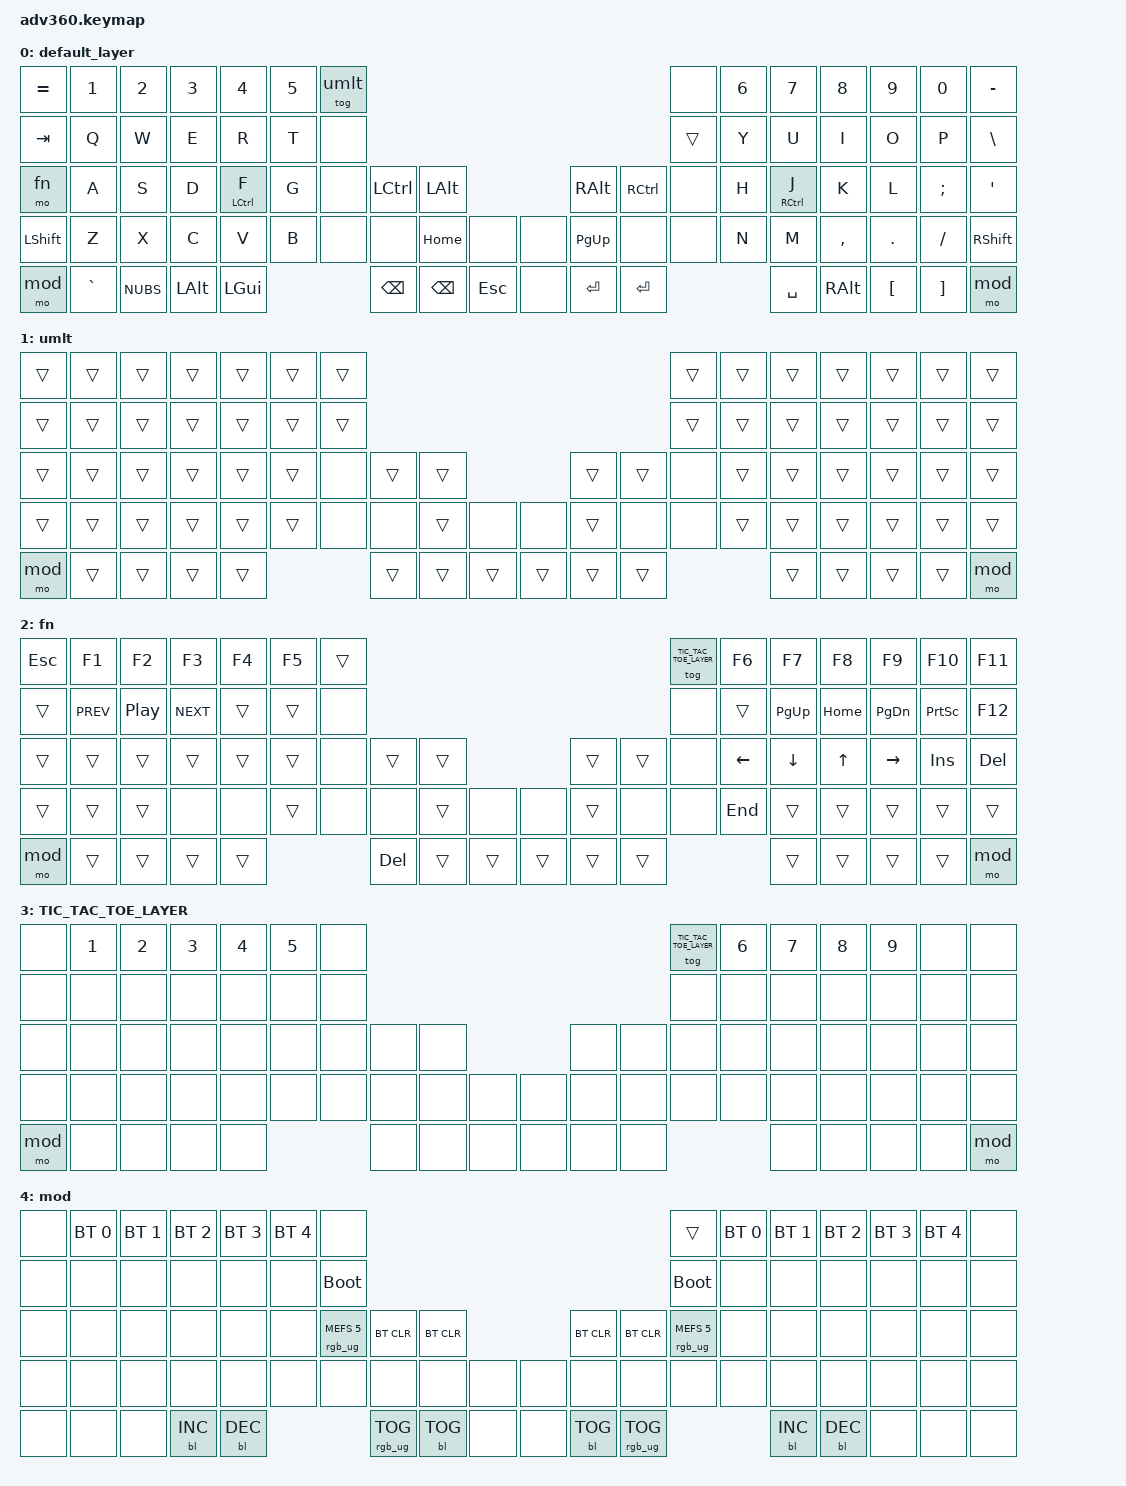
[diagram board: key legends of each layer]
#include <behaviors.dtsi>
#include <dt-bindings/zmk/keys.h>
#include <dt-bindings/zmk/bt.h>
#include <dt-bindings/zmk/rgb.h>
#include <dt-bindings/zmk/backlight.h>

#define umlt 1
#define fn 2
#define TIC_TAC_TOE_LAYER 3
#define mod 4


&mt {
    retro-tap;
};

/ {
    behaviors {
      #include "macros.dtsi"

      hm: homerow_mods {
          compatible = "zmk,behavior-hold-tap";
          label = "HOMEROW_MODS";
          #binding-cells = <2>;
          tapping-term-ms = <150>;
          quick_tap_ms = <175>;
          flavor = "tap-preferred";
          bindings = <&kp>, <&kp>;
      };
    };

  keymap {
    compatible = "zmk,keymap";

// LAYER_START
    default_layer {
      bindings = <
&kp EQUAL   &kp N1      &kp N2      &kp N3      &kp N4      &kp N5      &tog umlt                                                                           &none       &kp N6      &kp N7      &kp N8      &kp N9      &kp N0      &kp MINUS   
&kp TAB     &kp Q       &kp W       &kp E       &kp R       &kp T       &none                                                                               &trans      &kp Y       &kp U       &kp I       &kp O       &kp P       &kp BSLH    
&mo fn      &kp A       &kp S       &kp D       &mt LCTL F  &kp G       &none       &kp LCTRL   &kp LALT                            &kp RALT    &kp RCTRL   &none       &kp H       &mt RCTL J  &kp K       &kp L       &kp SEMI    &kp SQT     
&kp LSHIFT  &kp Z       &kp X       &kp C       &kp V       &kp B       &none       &none       &kp HOME    &none       &none       &kp PG_UP   &none       &none       &kp N       &kp M       &kp COMMA   &kp DOT     &kp SLASH   &kp RSHIFT  
&mo mod     &kp GRAVE   &kp NUBS    &kp LALT    &kp LGUI                            &kp BSPC    &kp BSPC    &kp ESCAPE  &none       &kp ENTER   &kp ENTER                           &kp SPACE   &kp RALT    &kp LBKT    &kp RBKT    &mo mod     
      >;
    };
    umlt {
      bindings = <
&trans      &trans      &trans      &trans      &trans      &trans      &trans                                                                              &trans      &trans      &trans      &trans      &trans      &trans      &trans      
&trans      &trans      &trans      &trans      &trans      &trans      &trans                                                                              &trans      &trans      &trans      &trans      &trans      &trans      &trans      
&trans      &trans      &trans      &trans      &trans      &trans      &none       &trans      &trans                              &trans      &trans      &none       &trans      &trans      &trans      &trans      &trans      &trans      
&trans      &trans      &trans      &trans      &trans      &trans      &none       &none       &trans      &none       &none       &trans      &none       &none       &trans      &trans      &trans      &trans      &trans      &trans      
&mo mod     &trans      &trans      &trans      &trans                              &trans      &trans      &trans      &trans      &trans      &trans                              &trans      &trans      &trans      &trans      &mo mod     
      >;
    };
    fn {
      bindings = <
&kp ESCAPE  &kp F1      &kp F2      &kp F3      &kp F4      &kp F5      &trans                                                                              &tog TIC_TAC_TOE_LAYER&kp F6      &kp F7      &kp F8      &kp F9      &kp F10     &kp F11     
&trans      &kp C_PREV  &kp C_PP    &kp C_NEXT  &trans      &trans      &none                                                                               &none       &trans      &kp PG_UP   &kp HOME    &kp PG_DN   &kp PSCRN   &kp F12     
&trans      &trans      &trans      &trans      &trans      &trans      &none       &trans      &trans                              &trans      &trans      &none       &kp LEFT    &kp DOWN    &kp UP      &kp RIGHT   &kp INSERT  &kp DELETE  
&trans      &trans      &trans      &none       &none       &trans      &none       &none       &trans      &none       &none       &trans      &none       &none       &kp END     &trans      &trans      &trans      &trans      &trans      
&mo mod     &trans      &trans      &trans      &trans                              &kp DELETE  &trans      &trans      &trans      &trans      &trans                              &trans      &trans      &trans      &trans      &mo mod     
      >;
    };
    TIC_TAC_TOE_LAYER {
      bindings = <
&none       &kp N1      &kp N2      &kp N3      &kp N4      &kp N5      &none                                                                               &tog TIC_TAC_TOE_LAYER&kp N6      &kp N7      &kp N8      &kp N9      &none       &none       
&none       &none       &none       &none       &none       &none       &none                                                                               &none       &none       &none       &none       &none       &none       &none       
&none       &none       &none       &none       &none       &none       &none       &none       &none                               &none       &none       &none       &none       &none       &none       &none       &none       &none       
&none       &none       &none       &none       &none       &none       &none       &none       &none       &none       &none       &none       &none       &none       &none       &none       &none       &none       &none       &none       
&mo mod     &none       &none       &none       &none                               &none       &none       &none       &none       &none       &none                               &none       &none       &none       &none       &mo mod     
      >;
    };
// LAYER_END

    mod {
      bindings = <
        &none &bt BT_SEL 0 &bt BT_SEL 1 &bt BT_SEL 2 &bt BT_SEL 3 &bt BT_SEL 4 &none                                                                                                          &trans                 &bt BT_SEL 0 &bt BT_SEL 1 &bt BT_SEL 2 &bt BT_SEL 3 &bt BT_SEL 4 &none
        &none &none        &none        &none        &none        &none        &bootloader                                                                                                    &bootloader            &none        &none        &none        &none        &none        &none
        &none &none        &none        &none        &none        &none        &rgb_ug RGB_MEFS_CMD 5                 &bt BT_CLR &bt BT_CLR             &bt BT_CLR &bt BT_CLR                 &rgb_ug RGB_MEFS_CMD 5 &none        &none        &none        &none        &none        &none
        &none &none        &none        &none        &none        &none                               &none           &none      &none      &none &none &none      &none      &none                                  &none        &none        &none        &none        &none        &none
        &none &none        &none        &bl BL_INC   &bl BL_DEC                                       &rgb_ug RGB_TOG &bl BL_TOG &none                  &none      &bl BL_TOG &rgb_ug RGB_TOG                                     &bl BL_INC   &bl BL_DEC   &none        &none        &none
      >;
    };

  };
};
